# SF32LB55x register map
File version: 1.0
CPU: CM33 r0p1, little endian, MPU, FPU, 3 interrupt priority bits
Registers are 32-bit, read-write, reset 0x0 unless marked. A register's access mark holds for its fields unless they carry their own. Offsets are from the block's base; [hi:lo] are bit positions.

## EXTDMA
Base 0x40017000
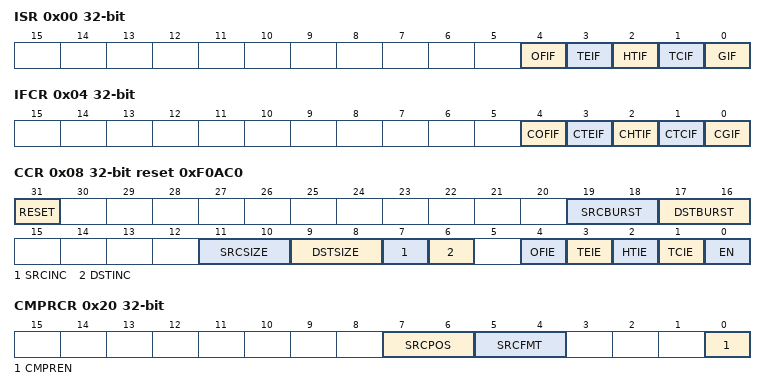
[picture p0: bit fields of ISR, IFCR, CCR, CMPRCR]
0x00 ISR — interrupt status register
  [4] OFIF — OFIF, overflow flag
  [3] TEIF — TEIF, transfer error flag
  [2] HTIF — HTIF, half transfer flag
  [1] TCIF — TCIF, transfer complete flag
  [0] GIF — GIF, global interrupt flag
0x04 IFCR — interrupt clear register
  [4] COFIF — COFIF, overflow flag clear
  [3] CTEIF — CTEIF, transfer error flag clear
  [2] CHTIF — CHTIF, half transfer flag clear
  [1] CTCIF — CTCIF, transfer complete flag clear
  [0] CGIF — CGIF, global interrupt flag clear
0x08 CCR reset 0xF0AC0 — channel control register
  [31] RESET — Software reset, will clear extdma status. Active high. Will be cleared by HW automatically
  [19:18] SRCBURST — source burst transfer configuration 00: single transfer 01: INCR4 (incremental burst of 4 beats) 10: INCR8 (incremental burst of 8 beats) 11: INCR16 (incremental burst of 16 beats)
  [17:16] DSTBURST — destination burst transfer configuration 00: single transfer 01: INCR4 (incremental burst of 4 beats) 10: INCR8 (incremental burst of 8 beats) 11: INCR16 (incremental burst of 16 beats)
  [11:10] SRCSIZE — source size Defines the data size of each DMA transfer to the source memory. Should be fixed to 10 (32 bits), word access allowed only.
  [9:8] DSTSIZE — destination size Defines the data size of each DMA transfer to the destination memory. Should be fixed to 10 (32 bits), word access allowed only.
  [7] SRCINC — source increment mode Defines the increment mode for each DMA transfer to the source memory. 0: disabled 1: enabled
  [6] DSTINC — destination increment mode Defines the increment mode for each DMA transfer to the destination memory. 0: disabled 1: enabled
  [4] OFIE — overflow interrupt enable 0: disabled 1: enabled
  [3] TEIE — transfer error interrupt enable 0: disabled 1: enabled
  [2] HTIE — half transfer interrupt enable 0: disabled 1: enabled
  [1] TCIE — transfer complete interrupt enable 0: disabled 1: enabled
  [0] EN — extdma enable. Will be cleared if ccr_reset is written
0x0C CNDTR — number of data register
  [19:0] NDT — number of data to transfer (0 to 2^20 - 1) This field is updated by hardware when the channel is enabled: It is decremented after each transfer, indicating the remaining amount of data items to transfer. It is kept at zero when the programmed amount of data to transfer is reached. If this field is zero, no transfer can be served whatever the channel enabled or not
0x10 SRCAR — source address register
  [31:0] SRCADDR — source address It contains the base address of the source data to be read. Should be word aligned
0x14 DSTAR — destination 0 address register
  [31:0] DSTADDR — destination address It contains the base address of the destination data to be written. Should be word aligned
0x20 CMPRCR — Image Compression control register
  [7:6] SRCPOS — Starting byte position in the first word of the source frame Valid starting positon includes: RGB565: 0x0,0x2 RGB888: 0x0, 0x1, 0x2, 0x3 ARGB8888: 0x0
  [5:4] SRCFMT — Source frame format 00: 16-bit RGB 5:6:5 01: 24-bit RGB 8:8:8 10: 32-bit ARGB 8:8:8:8 11: Reserved
  [0] CMPREN — Compression enable
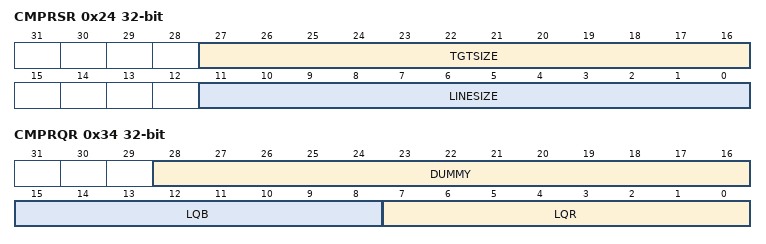
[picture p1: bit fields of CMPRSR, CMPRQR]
0x24 CMPRSR — Compression size register
  [27:16] TGTSIZE — output target size of each line after compression. output data size of each line is tgtsize*3*2 bytes
  [11:0] LINESIZE — column number (pixel number) of each line. Input data size of each line is linesize*(size per pixel)
0x28 CMPRNDTR — number of compression output data register
  [19:0] CMPRNDT — If compression enabled, cmprndt is the number of data to transfer after compression (0 to 2^20 - 1) and have to be written by software before compression. The value should be TGTSIZE*6*line_number/4 in compression mode. If compression disabled, it reads the number of data that extdma has written into destination address. Software do not need to write this field. This field is updated by hardware when extdma enabled
0x2C CMPRCFG0 reset 0x80023307 — Compression configuration 0
  [31:0] CFG — Compression configuration
0x30 CMPRCFG1 reset 0x1055982 — Compression configuration 1
  [31:0] CFG — Compression configuration
0x34 CMPRQR — Compression quality register
  [28:16] DUMMY — line least dummy word in one frame, update every frame.
  [15:8] LQB — low quality block number. the bigger of this number, the worse compressed image quality
  [7:0] LQR — quality sum to low qulity block number ratio. the bigger of this number, the worse compressed image quality.
0x38 CMPRDR — Compression debug register
  [6:0] MAXBUF — record of max used buffer during compression output
